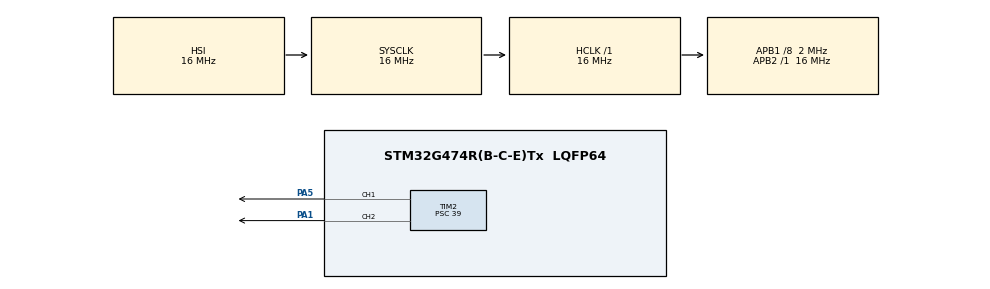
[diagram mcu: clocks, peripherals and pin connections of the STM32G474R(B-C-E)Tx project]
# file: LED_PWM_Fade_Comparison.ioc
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Mcu.Family=STM32G4
Mcu.Name=STM32G474R(B-C-E)Tx
Mcu.Package=LQFP64
NVIC.PriorityGroup=NVIC_PRIORITYGROUP_4
NVIC.TIM2_IRQn=true\:0\:0\:false\:false\:true\:true\:true\:true
PA1.Signal=S_TIM2_CH2
PA5.Signal=S_TIM2_CH1
ProjectManager.HeapSize=0x200
ProjectManager.StackSize=0x400
ProjectManager.TargetToolchain=STM32CubeIDE
RCC.AHBFreq_Value=16000000
RCC.APB1CLKDivider=RCC_HCLK_DIV8
RCC.APB1Freq_Value=2000000
RCC.APB1TimFreq_Value=4000000
RCC.APB2Freq_Value=16000000
RCC.APB2TimFreq_Value=16000000
RCC.CortexFreq_Value=16000000
RCC.EXTERNAL_CLOCK_VALUE=12288000
RCC.HCLKFreq_Value=16000000
RCC.HSE_VALUE=8000000
RCC.HSI48_VALUE=48000000
RCC.HSI_VALUE=16000000
RCC.LSE_VALUE=32768
RCC.SYSCLKFreq_VALUE=16000000
RCC.USBFreq_Value=64000000
RCC.VCOOutputFreq_Value=128000000
SH.S_TIM2_CH1.0=TIM2_CH1,PWM Generation1 CH1
SH.S_TIM2_CH2.0=TIM2_CH2,PWM Generation2 CH2
TIM2.Channel-PWM\ Generation1\ CH1=TIM_CHANNEL_1
TIM2.Channel-PWM\ Generation2\ CH2=TIM_CHANNEL_2
TIM2.PeriodNoDither=999
TIM2.Prescaler=39
TIM2.PulseNoDither_1=249
TIM2.PulseNoDither_2=249
VP_SYS_VS_DBSignals.Mode=DisableDeadBatterySignals
VP_TIM2_VS_ClockSourceINT.Mode=Internal
board=custom

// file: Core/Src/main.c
/* USER CODE BEGIN Header */
/**
  ******************************************************************************
  * @file           : main.c
  * @brief          : Main program body
  ******************************************************************************
  */
/* USER CODE END Header */
#include "main.h"
#include "tim.h"
#include "gpio.h"

/* USER CODE BEGIN PD */
#define CYCLE_DELAY (60)
#define DUTY_INC (20)
#define NUM_INTERRUPTS_PER_CYCLE (6) // Numero di interrupt per ciclo completo del secondo LED
/* USER CODE END PD */

/* USER CODE BEGIN PV */
// Inizializzato a 0. Il valore reale viene letto nel main dopo l'init.
uint32_t period_tim_2 = 0;
/* USER CODE END PV */

void SystemClock_Config(void);
/* USER CODE BEGIN PFP */
void increase_duty_cycle(TIM_HandleTypeDef *htim, uint32_t Channel, uint32_t period);
/* USER CODE END PFP */

int main(void)
{

  /* MCU Configuration--------------------------------------------------------*/

  /* Reset of all peripherals, Initializes the Flash interface and the Systick. */
  HAL_Init();

  /* Configure the system clock */
  SystemClock_Config();

  /* Initialize all configured peripherals */
  MX_GPIO_Init();
  MX_TIM2_Init();
  /* USER CODE BEGIN 2 */
  // 1. Recupera il valore di ARR (periodo) dopo l'inizializzazione del timer
  period_tim_2 = __HAL_TIM_GET_AUTORELOAD(&htim2);

  // 2. Avvia il PWM sui Canali 1 e 2
  HAL_TIM_PWM_Start(&htim2, TIM_CHANNEL_1);
  HAL_TIM_PWM_Start(&htim2, TIM_CHANNEL_2);

  // 3. Avvia il timer in interrupt per gestire il secondo LED
  HAL_TIM_Base_Start_IT(&htim2);
  /* USER CODE END 2 */

  /* Infinite loop */
  while (1)
  {

    /* USER CODE BEGIN 3 */
    // Incrementa il duty cycle
    increase_duty_cycle(&htim2, TIM_CHANNEL_1, period_tim_2);

    // Attesa prima del prossimo incremento
    HAL_Delay(CYCLE_DELAY);
  }
  /* USER CODE END 3 */
}

void SystemClock_Config(void)
{
  RCC_OscInitTypeDef RCC_OscInitStruct = {0};
  RCC_ClkInitTypeDef RCC_ClkInitStruct = {0};

  /** Configure the main internal regulator output voltage
  */
  HAL_PWREx_ControlVoltageScaling(PWR_REGULATOR_VOLTAGE_SCALE1);

  /** Initializes the RCC Oscillators according to the specified parameters
  * in the RCC_OscInitTypeDef structure.
  */
  RCC_OscInitStruct.OscillatorType = RCC_OSCILLATORTYPE_HSI;
  RCC_OscInitStruct.HSIState = RCC_HSI_ON;
  RCC_OscInitStruct.HSICalibrationValue = RCC_HSICALIBRATION_DEFAULT;
  RCC_OscInitStruct.PLL.PLLState = RCC_PLL_NONE;
  if (HAL_RCC_OscConfig(&RCC_OscInitStruct) != HAL_OK)
  {
    Error_Handler();
  }

  /** Initializes the CPU, AHB and APB buses clocks
  */
  RCC_ClkInitStruct.ClockType = RCC_CLOCKTYPE_HCLK|RCC_CLOCKTYPE_SYSCLK
                              |RCC_CLOCKTYPE_PCLK1|RCC_CLOCKTYPE_PCLK2;
  RCC_ClkInitStruct.SYSCLKSource = RCC_SYSCLKSOURCE_HSI;
  RCC_ClkInitStruct.AHBCLKDivider = RCC_SYSCLK_DIV1;
  RCC_ClkInitStruct.APB1CLKDivider = RCC_HCLK_DIV8;
  RCC_ClkInitStruct.APB2CLKDivider = RCC_HCLK_DIV1;

  if (HAL_RCC_ClockConfig(&RCC_ClkInitStruct, FLASH_LATENCY_0) != HAL_OK)
  {
    Error_Handler();
  }
}

/* USER CODE BEGIN 4 */
/**
  * @brief  Incrementa il Duty Cycle e lo cicla usando il modulo del periodo.
  * @param  htim: Puntatore all'handle del timer
  * @param  Channel: Canale del timer (es. TIM_CHANNEL_1)
  * @param  period: Valore massimo (ARR) del timer
  */
void increase_duty_cycle(TIM_HandleTypeDef *htim, uint32_t Channel, uint32_t period) {
    if (period == 0) return; // Evita errori matematici

    // Legge il valore attuale di Compare (CCR)
    uint32_t pulse = __HAL_TIM_GET_COMPARE(htim, Channel);

    // Incremento e cicla con modulo
    pulse = (pulse + DUTY_INC) % (period + 1);

    // Applica il nuovo valore al Compare
    __HAL_TIM_SET_COMPARE(htim, Channel, pulse);
}

/**
  * @brief  Callback dell'interrupt del timer - gestisce il secondo LED
  * @param  htim: Puntatore all'handle del timer
  */
void HAL_TIM_PeriodElapsedCallback(TIM_HandleTypeDef *htim)
{
    if (htim == &htim2)
    {
        static uint32_t tick = 0;
        tick++;

        // Incrementa il duty del secondo LED ogni 6 interrupt (~60 ms a 100 Hz) per sincronizzarlo con LED 1
        if (tick >= NUM_INTERRUPTS_PER_CYCLE)
        {
            tick = 0;
            increase_duty_cycle(&htim2, TIM_CHANNEL_2, period_tim_2);
        }
    }
}
/* USER CODE END 4 */

void Error_Handler(void)
{
  __disable_irq();
  while (1)
  {
  }
}
